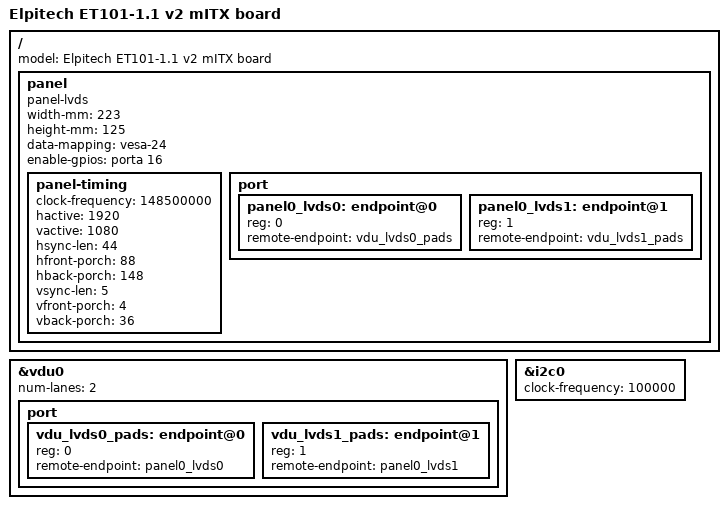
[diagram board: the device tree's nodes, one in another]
// SPDX-License-Identifier: GPL-2.0
/*
 * Elpitech ET101-1.1 v2 Mini-ITX board device tree
 */

/dts-v1/;

#include "bm-et101.dtsi"

/ {

	model = "Elpitech ET101-1.1 v2 mITX board";

	panel {
		compatible = "panel-lvds";
		width-mm = <223>;
		height-mm = <125>;
		data-mapping = "vesa-24";
		enable-gpios = <&porta 16 GPIO_ACTIVE_HIGH>;
		panel-timing {
		// 1920x1080 @60Hz
			clock-frequency = <148500000>;
			hactive = <1920>;
			vactive = <1080>;
			hsync-len = <44>;
			hfront-porch = <88>;
			hback-porch = <148>;
			vsync-len = <5>;
			vfront-porch = <4>;
			vback-porch = <36>;
		};
		port {
			#address-cells = <1>;
			#size-cells = <0>;
			panel0_lvds0: endpoint@0 {
				reg = <0>;
				remote-endpoint = <&vdu_lvds0_pads>;
			};
			panel0_lvds1: endpoint@1 {
				reg = <1>;
				remote-endpoint = <&vdu_lvds1_pads>;
			};
		};
	};
};

&vdu0 {
	status = "okay";
	num-lanes = <2>;
	port {
		#address-cells = <1>;
		#size-cells = <0>;
		vdu_lvds0_pads: endpoint@0 {
			reg = <0>;
			remote-endpoint = <&panel0_lvds0>;
		};
		vdu_lvds1_pads: endpoint@1 {
			reg = <1>;
			remote-endpoint = <&panel0_lvds1>;
		};
	};
};

&i2c0 {
	clock-frequency = <100000>;
};
